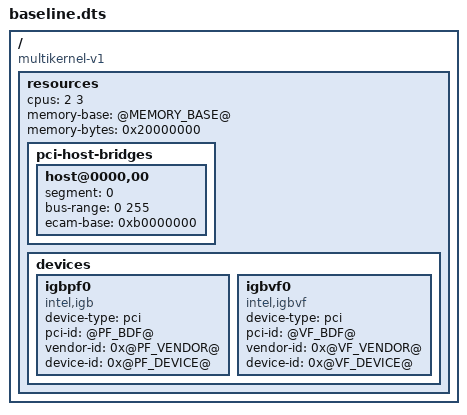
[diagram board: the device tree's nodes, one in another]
/dts-v1/;

/ {
	compatible = "multikernel-v1";
	resources {
		cpus = /bits/ 64 <2 3>;
		memory-base = <@MEMORY_BASE@>;
		memory-bytes = <0x20000000>;
		pci-host-bridges {
			host@0000,00 {
				segment = <0>;
				bus-range = <0 255>;
				ecam-base = /bits/ 64 <0xb0000000>;
			};
		};
		devices {
			igbpf0 {
				device-type = "pci";
				compatible = "intel,igb";
				pci-id = "@PF_BDF@";
				vendor-id = <0x@PF_VENDOR@>;
				device-id = <0x@PF_DEVICE@>;
			};

			igbvf0 {
				device-type = "pci";
				compatible = "intel,igbvf";
				pci-id = "@VF_BDF@";
				vendor-id = <0x@VF_VENDOR@>;
				device-id = <0x@VF_DEVICE@>;
			};
		};
	};
};
